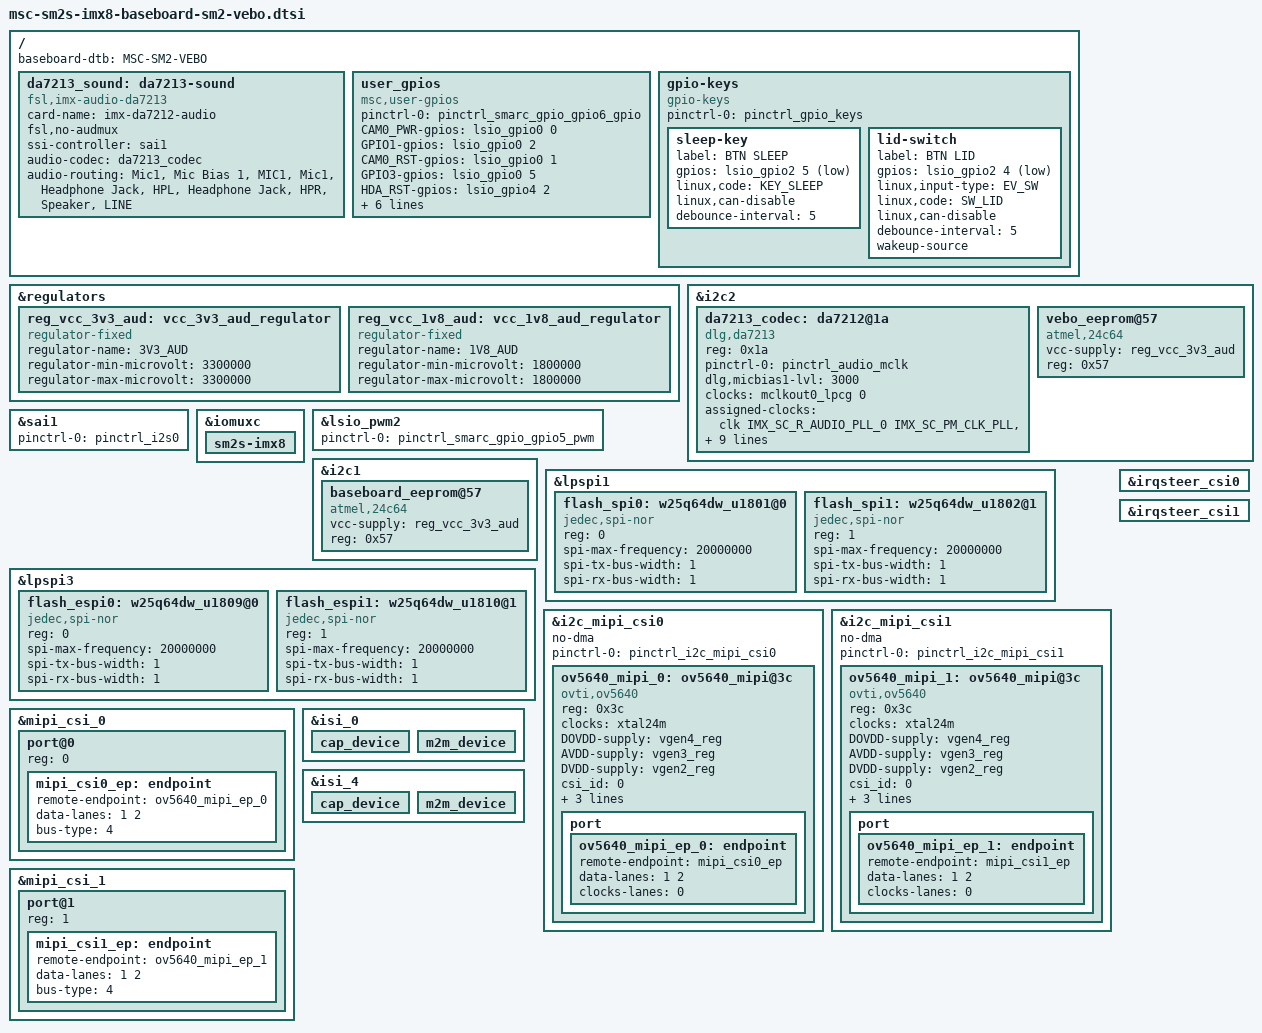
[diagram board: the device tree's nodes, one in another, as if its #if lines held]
/** @file      msc-sm2s-imx8-baseboard-sm2-vebo.dtsi

    @copyright Copyright (C) 2022 by MSC Technologies GmbH
    SPDX-License Identifier: GPL-2.0-or-later

    @author    Dieter Hermanns

    @details   Provides baseboard mappings that are merged at runtime with the CPU device tree.
*/

/dts-v1/;
/plugin/;

#include <dt-bindings/firmware/imx/rsrc.h>
#include <dt-bindings/gpio/gpio.h>
#include <dt-bindings/input/input.h>
#include <dt-bindings/pinctrl/pads-imx8qm-pintool-compatible.h>

/ {
	fragment@0 {
		target-path = "/";

		__overlay__ {
			baseboard-dtb = "MSC-SM2-VEBO"; /* just informal */
		};
	};

	fragment@1 {
		target = <&regulators>;
		__overlay__ {
			reg_vcc_3v3_aud: vcc_3v3_aud_regulator {
				compatible = "regulator-fixed";
				regulator-name = "3V3_AUD";
				regulator-min-microvolt = <3300000>;
				regulator-max-microvolt = <3300000>;
			};

			reg_vcc_1v8_aud: vcc_1v8_aud_regulator {
				compatible = "regulator-fixed";
				regulator-name = "1V8_AUD";
				regulator-min-microvolt = <1800000>;
				regulator-max-microvolt = <1800000>;
			};
		};
	};

	fragment@2 {
		target = <&i2c2>;
		__overlay__ {
			#address-cells = <1>;
			#size-cells = <0>;
			da7213_codec: da7212@1a {
				compatible = "dlg,da7213";
				reg = <0x1a>;
				pinctrl-names = "default";
				pinctrl-0 = <&pinctrl_audio_mclk>;
				dlg,micbias1-lvl = <3000>;
				clocks = <&mclkout0_lpcg 0>;
				clock-names = "mclk";
				assigned-clocks = <&clk IMX_SC_R_AUDIO_PLL_0 IMX_SC_PM_CLK_PLL>,
						  <&clk IMX_SC_R_AUDIO_PLL_0 IMX_SC_PM_CLK_SLV_BUS>,
						  <&clk IMX_SC_R_AUDIO_PLL_0 IMX_SC_PM_CLK_MST_BUS>,
						  <&mclkout0_lpcg 0>;

				/* asrc0 seems to be configured to use IMX8QM_AUD_ACM_AUD_REC_CLK0_DIV as MCLK_OUT0
				   Therefore IMX8QM_AUD_MCLKOUT0 is not actually configured by this value (is noop) but mirrors the setting
				   IMX8QM_AUD_ACM_AUD_REC_CLK0_DIV */
				assigned-clock-rates = <786432000>, <49152000>, <12288000>;
				VDDA-supply = <&reg_vcc_3v3_aud>;
				VDD-supply = <&reg_vcc_1v8_aud>;
				VDDIO-supply = <&reg_vcc_1v8_aud>;
				VDDMIC-supply = <&reg_vcc_3v3_aud>;
				status = "okay";
			};

			vebo_eeprom@57 {
				compatible = "atmel,24c64";
				vcc-supply = <&reg_vcc_3v3_aud>;
				reg = <0x57>;
			};
		};
	};


	fragment@3 {
		target = <&sai1>;
		__overlay__ {
		/* MEK Board has these clocks also assigned. But on the SM2-MB-EP1
		   the clocks assigned to the codec are sufficient, therefore we
		   have disabled them. */
/*
			clocks = <&sai1_lpcg 0>;
			clock-names = "mclk";
			assigned-clocks = <&clk IMX_SC_R_AUDIO_PLL_0 IMX_SC_PM_CLK_PLL>,
				<&clk IMX_SC_R_AUDIO_PLL_0 IMX_SC_PM_CLK_SLV_BUS>,
				<&clk IMX_SC_R_AUDIO_PLL_0 IMX_SC_PM_CLK_MST_BUS>,
				<&sai1_lpcg 0>;
*/
			pinctrl-names = "default";
			pinctrl-0 = <&pinctrl_i2s0>;
			status = "okay";
		};
	};

	fragment@4 {
		target-path = "/";
		__overlay__ {
			da7213_sound: da7213-sound {
				compatible = "fsl,imx-audio-da7213";
				card-name = "imx-da7212-audio";
				fsl,no-audmux;
				ssi-controller = <&sai1>;
				audio-codec = <&da7213_codec>;
				audio-routing =
						"Mic1", "Mic Bias 1",
						"MIC1", "Mic1",
						"Headphone Jack", "HPL",
						"Headphone Jack", "HPR",
						"Speaker", "LINE";
				status = "okay";
			};
		};
	};

	fragment@5 {
		target-path = "/";
		__overlay__ {
			user_gpios {
				compatible = "msc,user-gpios";
				pinctrl-names = "default";
				pinctrl-0 =
					<&pinctrl_smarc_gpio_gpio6_gpio>; // should be counting pulses

				CAM0_PWR-gpios = <&lsio_gpio0 0 0>; // GPIO0
				GPIO1-gpios = <&lsio_gpio0 2 0>;
				CAM0_RST-gpios = <&lsio_gpio0 1 0>; // GPIO2
				GPIO3-gpios = <&lsio_gpio0 5 0>;
				// GPIO5 is used as special function FAN_PWM
				HDA_RST-gpios = <&lsio_gpio4 2 0>; // GPIO4
				FAN_TACHIN-gpios = <&lsio_gpio0 16 0>; // GPIO6
				GPIO7-gpios = <&lsio_gpio4 1 0>;
#if MODULE_MES_REVISION != 20
				GPIO8-gpios = <&lsio_gpio2 27 0>;
				GPIO9-gpios = <&lsio_gpio1 18 0>;
				GPIO10-gpios = <&lsio_gpio2 29 0>;
				GPIO11-gpios = <&lsio_gpio1 17 0>;
#else
				GPIO8-gpios = <&lsio_gpio0 30 0>;
				GPIO9-gpios = <&lsio_gpio0 31 0>;
				GPIO10-gpios = <&lsio_gpio1 0 0>;
				GPIO11-gpios = <&lsio_gpio1 1 0>;
#endif
			};

			gpio-keys {
				compatible = "gpio-keys";
				pinctrl-names = "default";
				pinctrl-0 = <&pinctrl_gpio_keys>;

				sleep-key {
					label = "BTN SLEEP"; // signal SLEEP#
					gpios = <&lsio_gpio2 5 GPIO_ACTIVE_LOW>;
					linux,code = <KEY_SLEEP>;
					linux,can-disable;
					debounce-interval = <5>;
				};

				lid-switch {
					label = "BTN LID"; // signal LID#
					gpios = <&lsio_gpio2 4 GPIO_ACTIVE_LOW>;
					linux,input-type = <EV_SW>;
					linux,code = <SW_LID>;
					linux,can-disable;
					debounce-interval = <5>;
					wakeup-source;
				};
			};
		};
	};

	fragment@6 {
		target = <&iomuxc>;
		__overlay__ {
			sm2s-imx8 {
				#include "msc-sm2s-imx8-pinmux-gpio5-pwm.dtsi"
			};
		};
	};

	fragment@7 {
		target = <&lsio_pwm2>;
		__overlay__ {
			status = "okay";
				pinctrl-names = "default";
				pinctrl-0 = <&pinctrl_smarc_gpio_gpio5_pwm>;
		};
	};

	fragment@8 {
		target = <&i2c1>;
		__overlay__ {
			#address-cells = <1>;
			#size-cells = <0>;
			baseboard_eeprom@57 {
				compatible = "atmel,24c64";
				vcc-supply = <&reg_vcc_3v3_aud>;
				reg = <0x57>;
			};
		};
	};

	fragment@9 {
		target = <&lpspi1>;
		__overlay__ {
			#address-cells = <1>;
			#size-cells = <0>;

			flash_spi0: w25q64dw_u1801@0 { // this one is socketed
				reg = <0>;
				#address-cells = <1>;
				#size-cells = <1>;
				compatible = "jedec,spi-nor";
				spi-max-frequency = <20000000>;
				spi-tx-bus-width = <1>;
				spi-rx-bus-width = <1>;
			};

			flash_spi1: w25q64dw_u1802@1 {
				reg = <1>;
				#address-cells = <1>;
				#size-cells = <1>;
				compatible = "jedec,spi-nor";
				spi-max-frequency = <20000000>;
				spi-tx-bus-width = <1>;
				spi-rx-bus-width = <1>;
			};
		};
	};

	fragment@10 {
		target = <&lpspi3>;
		__overlay__ {
			#address-cells = <1>;
			#size-cells = <0>;
			flash_espi0: w25q64dw_u1809@0 {
				reg = <0>;
				#address-cells = <1>;
				#size-cells = <1>;
				compatible = "jedec,spi-nor";
				spi-max-frequency = <20000000>;
				spi-tx-bus-width = <1>;
				spi-rx-bus-width = <1>;
			};
			flash_espi1: w25q64dw_u1810@1 {
				reg = <1>;
				#address-cells = <1>;
				#size-cells = <1>;
				compatible = "jedec,spi-nor";
				spi-max-frequency = <20000000>;
				spi-tx-bus-width = <1>;
				spi-rx-bus-width = <1>;
			};
		};
	};

	fragment@11 {
		target = <&i2c_mipi_csi0>;
		__overlay__ {
			#address-cells = <1>;
			#size-cells = <0>;
			no-dma;
			status = "okay";
			pinctrl-names = "default";
			pinctrl-0 = <&pinctrl_i2c_mipi_csi0>;
			ov5640_mipi_0: ov5640_mipi@3c {
				compatible = "ovti,ov5640";
				reg = <0x3c>;
				clocks = <&xtal24m>;
				clock-names = "xclk";
				DOVDD-supply = <&vgen4_reg>; /* 1.8v */
				AVDD-supply = <&vgen3_reg>;  /* 2.8v */
				DVDD-supply = <&vgen2_reg>;  /* 1.5v */
				csi_id = <0>;
				mclk = <24000000>;
				mclk_source = <0>;
				mipi_csi;
				status = "okay";
				port {
					ov5640_mipi_ep_0: endpoint {
						remote-endpoint = <&mipi_csi0_ep>;
						data-lanes = <1 2>;
						clocks-lanes = <0>;
					};
				};
			};

		};
	};

	fragment@12 {
		target = <&i2c_mipi_csi1>;
		__overlay__ {
			#address-cells = <1>;
			#size-cells = <0>;
			no-dma;
			status = "okay";
			pinctrl-names = "default";
			pinctrl-0 = <&pinctrl_i2c_mipi_csi1>;
			ov5640_mipi_1: ov5640_mipi@3c {
				compatible = "ovti,ov5640";
				reg = <0x3c>;
				clocks = <&xtal24m>;
				clock-names = "xclk";
				DOVDD-supply = <&vgen4_reg>; /* 1.8v */
				AVDD-supply = <&vgen3_reg>;  /* 2.8v */
				DVDD-supply = <&vgen2_reg>;  /* 1.5v */
				csi_id = <0>;
				mclk = <24000000>;
				mclk_source = <0>;
				mipi_csi;
				status = "okay";
				port {
					ov5640_mipi_ep_1: endpoint {
						remote-endpoint = <&mipi_csi1_ep>;
						data-lanes = <1 2>;
						clocks-lanes = <0>;
					};
				};
			};
		};
	};

	fragment@13 {
		target = <&irqsteer_csi0>;
		__overlay__ {
			status = "okay";
		};
	};

	fragment@14 {
		target = <&irqsteer_csi1>;
		__overlay__ {
			status = "okay";
		};
	};

	fragment@15 {
		target = <&mipi_csi_0>;
		__overlay__  {
			#address-cells = <1>;
			#size-cells = <0>;
			/delete-property/virtual-channel;
			status = "okay";

			/* Camera 0  MIPI CSI-2 (CSIS0) */
			port@0 {
				reg = <0>;
				mipi_csi0_ep: endpoint {
					remote-endpoint = <&ov5640_mipi_ep_0>;
					data-lanes = <1 2>;
					bus-type = <4>;
				};
			};
		};
	};

	fragment@16 {
		target = <&isi_0>;
		__overlay__ {
			status = "okay";

			cap_device {
				status = "okay";
			};

			m2m_device {
				status = "okay";
			};
		};
	};

	fragment@17 {
		target = <&mipi_csi_1>;
		__overlay__  {
			#address-cells = <1>;
			#size-cells = <0>;
			/delete-property/virtual-channel;
			status = "okay";

			/* Camera 1  MIPI CSI-2 (CSIS1) */
			port@1 {
				reg = <1>;
				mipi_csi1_ep: endpoint {
					remote-endpoint = <&ov5640_mipi_ep_1>;
					data-lanes = <1 2>;
					bus-type = <4>;				};
			};
		};
	};

	fragment@18 {
		target = <&isi_4>;
		__overlay__ {
			status = "okay";

			cap_device {
				status = "okay";
			};

			m2m_device {
				status = "okay";
			};
		};
	};

};
